# Flash_6 register map
Vendor: Texas Instruments
Peripheral module from a debugger description file (folder msp430).
Registers are 16-bit, read-write, reset 0x0 unless marked. A register's access mark holds for its fields unless they carry their own. Offsets are as the file gives them; lines under a group give offsets from that group; [hi:lo] are bit positions; {n}, {i} and the like mark numbered series; 'fields as' and 'values as' point back to an identical list; <NAME> marks a mode.

## Flash
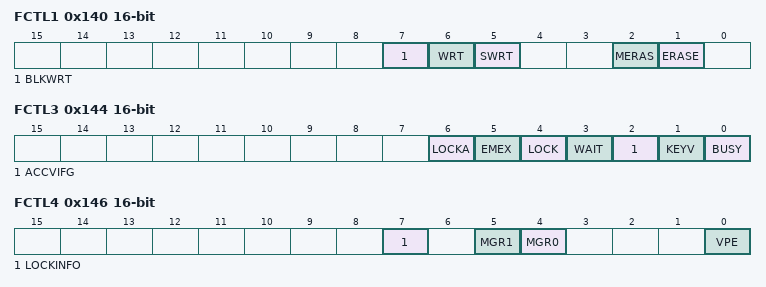
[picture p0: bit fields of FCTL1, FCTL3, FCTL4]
0x140 FCTL1 — FLASH Control 1
  [7] BLKWRT — Enable bit for Flash segment write
  [6] WRT — Enable bit for Flash write
  [5] SWRT — Smart Write enable
  [2] MERAS — Enable bit for Flash mass erase
  [1] ERASE — Enable bit for Flash segment erase
0x144 FCTL3 — FLASH Control 3
  [6] LOCKA — Segment A Lock bit: read = 1 - Segment is locked (read only)
  [5] EMEX — Flash Emergency Exit
  [4] LOCK — Lock bit: 1 - Flash is locked (read only)
  [3] WAIT — Wait flag for segment write
  [2] ACCVIFG — Flash Access violation flag
  [1] KEYV — Flash Key violation flag
  [0] BUSY — Flash busy: 1
0x146 FCTL4 — FLASH Control 4
  [7] LOCKINFO — Lock INFO Memory bit: read = 1 - Segment is locked (read only)
  [5] MGR1 — Marginal read 1 mode.
  [4] MGR0 — Marginal read 0 mode.
  [0] VPE — Voltage Changed during Program Error Flag
